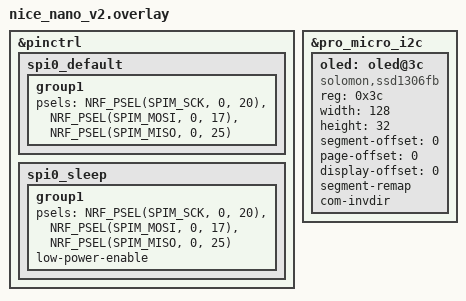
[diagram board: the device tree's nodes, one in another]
&pinctrl {
    spi0_default: spi0_default {
        group1 {
            psels = <NRF_PSEL(SPIM_SCK, 0, 20)>,
                <NRF_PSEL(SPIM_MOSI, 0, 17)>,
                <NRF_PSEL(SPIM_MISO, 0, 25)>;
        };
    };
    spi0_sleep: spi0_sleep {
        group1 {
            psels = <NRF_PSEL(SPIM_SCK, 0, 20)>,
                <NRF_PSEL(SPIM_MOSI, 0, 17)>,
                <NRF_PSEL(SPIM_MISO, 0, 25)>;
            low-power-enable;
        };
    };
};

&pro_micro_i2c {
    status = "okay";

    oled: oled@3c {
        compatible = "solomon,ssd1306fb";
        reg = <0x3c>;
        width = <128>;
        height = <32>;
        segment-offset = <0>;
        page-offset = <0>;
        display-offset = <0>;
        segment-remap;
        com-invdir;
        status = "okay";
    };
};
